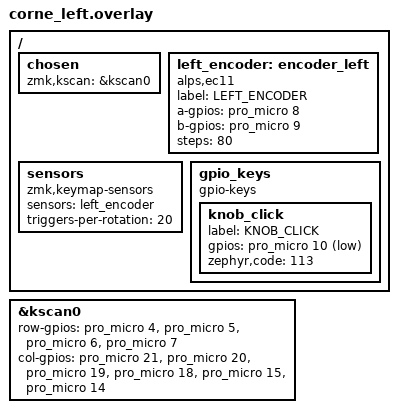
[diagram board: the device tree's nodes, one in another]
/* config/corne_left.overlay */
#include <dt-bindings/zmk/matrix_transform.h>

/ {
    chosen {
        zmk,kscan = &kscan0;
    };

    /* Knob (Pinos 8 e 9) */
    left_encoder: encoder_left {
        compatible = "alps,ec11";
        label = "LEFT_ENCODER";
        a-gpios = <&pro_micro 8 (GPIO_ACTIVE_HIGH | GPIO_PULL_UP)>;
        b-gpios = <&pro_micro 9 (GPIO_ACTIVE_HIGH | GPIO_PULL_UP)>;
        steps = <80>;
        status = "okay";
    };

    sensors {
        compatible = "zmk,keymap-sensors";
        sensors = <&left_encoder>;
        triggers-per-rotation = <20>;
    };
    
    /* Botão do Knob (Pino 10) */
    gpio_keys {
        compatible = "gpio-keys";
        knob_click: knob_click {
            label = "KNOB_CLICK";
            gpios = <&pro_micro 10 (GPIO_ACTIVE_LOW | GPIO_PULL_UP)>;
            zephyr,code = <113>; /* MUTE */
        };
    };
};

/* --- MATRIZ DE TECLAS (PINAGEM DO CHINÊS) --- */
&kscan0 {
    row-gpios
        = <&pro_micro 4 (GPIO_ACTIVE_HIGH | GPIO_PULL_DOWN)>
        , <&pro_micro 5 (GPIO_ACTIVE_HIGH | GPIO_PULL_DOWN)>
        , <&pro_micro 6 (GPIO_ACTIVE_HIGH | GPIO_PULL_DOWN)>
        , <&pro_micro 7 (GPIO_ACTIVE_HIGH | GPIO_PULL_DOWN)>
        ;
    
    col-gpios
        = <&pro_micro 21 GPIO_ACTIVE_HIGH>
        , <&pro_micro 20 GPIO_ACTIVE_HIGH>
        , <&pro_micro 19 GPIO_ACTIVE_HIGH>
        , <&pro_micro 18 GPIO_ACTIVE_HIGH>
        , <&pro_micro 15 GPIO_ACTIVE_HIGH>
        , <&pro_micro 14 GPIO_ACTIVE_HIGH>
        ;
};
